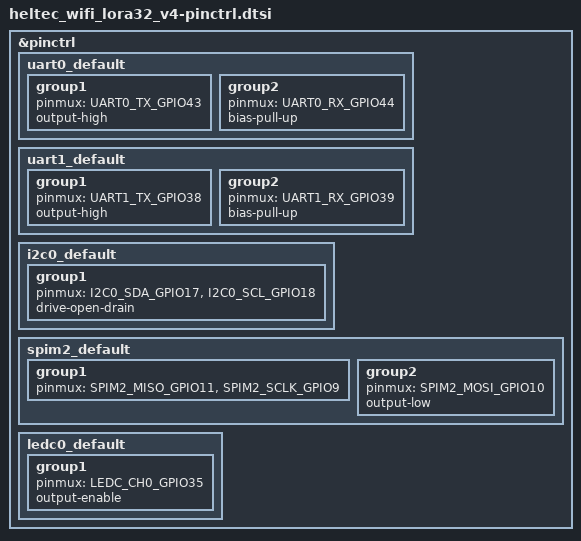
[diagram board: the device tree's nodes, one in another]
/*
 * SPDX-License-Identifier: Apache-2.0
 *
 * Pin control for the Heltec WiFi LoRa 32 (V4). Radio SPI, OLED I2C, console
 * UART and the white PWM LED are pinned exactly as on the V3 (the V4 kept the
 * same map). The one addition is uart1 for the on-board L76K GNSS:
 *   ESP RX <- GPIO39   (uart1 receives the module's NMEA here)
 *   ESP TX -> GPIO38   (uart1 transmits $PCAS/config to the module here)
 * NB: this is the OPPOSITE of what variant.h's *comments* imply. Those comments
 * ("GPS_TX 38 = bits toward the CPU") read backwards from how the reference code
 * actually wires it: firmware/src/gps/GPS.cpp sets rx_gpio=GPS_RX_PIN(39),
 * tx_gpio=GPS_TX_PIN(38) and calls Arduino begin(baud, 8N1, rxPin=39, txPin=38)
 * — i.e. ESP RX=39, ESP TX=38. Ground truth: stock Meshtastic on rzr2 logs
 * "Use GPIO39 for GPS RX / GPIO38 for GPS TX", detects the L76K and gets NMEA
 * time (2026-07-31). We originally trusted the comments (RX=38/TX=39) and got
 * total silence. VERIFY(hardware) on r8 — its GPS enable/standby pins move.
 */

#include <zephyr/dt-bindings/pinctrl/esp32s3-pinctrl.h>

&pinctrl {
	uart0_default: uart0_default {
		group1 {
			pinmux = <UART0_TX_GPIO43>;
			output-high;
		};

		group2 {
			pinmux = <UART0_RX_GPIO44>;
			bias-pull-up;
		};
	};

	uart1_default: uart1_default {
		group1 {
			pinmux = <UART1_TX_GPIO38>;	/* ESP TX -> module RX (matches stock) */
			output-high;
		};

		group2 {
			pinmux = <UART1_RX_GPIO39>;	/* ESP RX <- module TX (matches stock) */
			bias-pull-up;
		};
	};

	i2c0_default: i2c0_default {
		group1 {
			pinmux = <I2C0_SDA_GPIO17>,
				 <I2C0_SCL_GPIO18>;
			drive-open-drain;
		};
	};

	spim2_default: spim2_default {
		group1 {
			pinmux = <SPIM2_MISO_GPIO11>,
				 <SPIM2_SCLK_GPIO9>;
		};

		group2 {
			pinmux = <SPIM2_MOSI_GPIO10>;
			output-low;
		};
	};

	ledc0_default: ledc0_default {
		group1 {
			pinmux = <LEDC_CH0_GPIO35>;
			output-enable;
		};
	};
};
